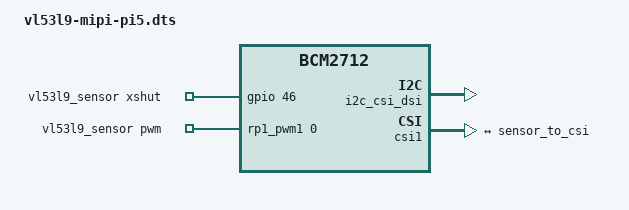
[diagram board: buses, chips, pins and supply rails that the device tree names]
// SPDX-License-Identifier: GPL-2.0-only
/*
 * VL53L9CX time-of-flight lidar (STEVAL-VL53L9) on Raspberry Pi 5 (BCM2712 + RP1).
 *
 * The VL53L9CX streams a RAW8 (datatype 0x2A, single data lane) MIPI CSI-2 image of
 * the ranging results and is configured over the camera connector I2C bus by
 * userspace (app/vl53l9_bringup). The kernel side only needs:
 *   - the RP1 CSI receiver (CFE) enabled with a 1-lane endpoint,
 *   - the connector I2C bus enabled so userspace can talk to the sensor,
 *   - a dummy CSI-2 sensor subdevice node matched by driver/dummy_cam.ko.
 *
 * XSHUT: on the 22-pin camera FFC, pin 17 (CAM_IO0) -- which the Pi 5 baseboard
 * normally uses as the camera-rail enable (cam0_reg / cam1_reg) -- reaches the
 * VL53L9's XSHUT pin. The STEVAL module has no separate power-enable net, so the
 * sensor node claims that line as xshut-gpios and the matching camN_reg is
 * disabled so it stops claiming/driving it. dummy_cam.ko then owns the line and
 * exposes /sys/devices/platform/vl53l9/xshut_{cycle,state}.
 * XSHUT HIGH = run, LOW = shutdown.
 *
 *   connector       CSI    I2C bus                  XSHUT (RP1 GPIO)  regulator
 *   MIPI1 (default) csi1   i2c_csi_dsi  -> i2c-4    46 (CD1_IO0)      cam1_reg
 *   MIPI0 (,cam0)   csi0   i2c_csi_dsi0 -> i2c-6    34 (CD0_IO0)      cam0_reg
 *
 * AP_CLK: the STEVAL ships strapped for a host-supplied reference clock on FFC
 * pin 18 (CAM_IO1 / "XCLK"). On the Pi 5 that pin is RP1 GPIO 35 (MIPI0) / 48
 * (MIPI1), which has no GPCLK function, only PWM1_CHAN0 (the fan uses
 * PWM1_CHAN3). The sensor node muxes that pin to pwm1 and dummy_cam runs channel
 * 0 at 8.33 MHz = 6 ticks of RP1's 50 MHz PWM clock, 50% duty (VL53L9 accepts
 * 6-27 MHz). Not 12 MHz: RP1 can't make it without a fractional divider, and the
 * STEVAL routes AP_CLK through a PI4ULS3V204 auto-direction level shifter rated
 * for 24 Mb/s push-pull (= a 12 MHz clock); 8.33 MHz (16.7 Mb/s) keeps margin. Boards modified to use the
 * onboard 12 MHz oscillator: load dummy_cam with ap_clk=0.
 *
 *   connector       AP_CLK pin (FFC 18)
 *   MIPI1 (default) RP1 GPIO 48 (CD1_IO1)
 *   MIPI0 (,cam0)   RP1 GPIO 35 (CD0_IO1; the kernel labels it CD0_IO0_MICDAT0)
 *
 * Every connector-specific setting (I2C bus, CSI port, XSHUT line, regulator,
 * AP_CLK pin) is switched together by the cam0 parameter, so the two variants can't disagree.
 *
 *     dtoverlay=vl53l9-mipi-pi5           # MIPI1 (main port)
 *     dtoverlay=vl53l9-mipi-pi5,cam0      # MIPI0 (second port)
 *
 * Optional: xshut_gpio=<n> overrides the XSHUT line number (applied after cam0);
 *           ap_clk_hz=<hz> changes the AP_CLK frequency (6-27 MHz; RP1 can only
 *           make 50 MHz / N, e.g. 8333333 (default), 10000000; 12500000 exceeds the
 *           board level shifter's 24 Mb/s rating).
 *
 * Build (needs the C preprocessor for the #include):
 *     make overlay      # or see README
 */
#include <dt-bindings/gpio/gpio.h>

/dts-v1/;
/plugin/;

/ {
	compatible = "brcm,bcm2712";

	i2c_frag: fragment@0 {
		target = <&i2c_csi_dsi>;
		__overlay__ {
			status = "okay";
		};
	};

	csi_frag: fragment@1 {
		target = <&csi1>;
		__overlay__ {
			status = "okay";

			port {
				csi_to_sensor: endpoint {
					remote-endpoint = <&sensor_to_csi>;
					clock-lanes = <0>;
					data-lanes = <1>;  /* VL53L9CX: single data lane */
				};
			};
		};
	};

	sensor_frag: fragment@2 {
		target-path = "/";
		__overlay__ {
			vl53l9_sensor: vl53l9 {
				compatible = "raspberrypi,dummy-csi2-sensor";
				status = "okay";

				/* Cell 1 (byte offset 4) is the GPIO number; patched by
				 * the cam0 / xshut_gpio parameters below. */
				xshut-gpios = <&gpio 46 GPIO_ACTIVE_HIGH>;

				/* AP_CLK: PWM1 channel 0 on FFC pin 18. The period
				 * cell is informational; dummy_cam programs the
				 * frequency from vl53l9,ap-clk-hz. */
				pinctrl-names = "default";
				pinctrl-0 = <&vl53l9_apclk_pins>;
				pwms = <&rp1_pwm1 0 80 0>;
				vl53l9,ap-clk-hz = <8333333>;

				port {
					sensor_to_csi: endpoint {
						remote-endpoint = <&csi_to_sensor>;
					};
				};
			};
		};
	};

	reg_frag: fragment@3 {
		target = <&cam1_reg>;
		__overlay__ {
			/* The baseboard treats this line as a camera-rail enable; on
			 * the STEVAL it is XSHUT. Left active, the fixed regulator
			 * would claim the GPIO (so dummy_cam could not) and, having no
			 * consumer, hold it LOW = sensor in shutdown. */
			status = "disabled";
		};
	};

	fragment@4 {
		target = <&rp1_gpio>;
		__overlay__ {
			vl53l9_apclk_pins: vl53l9_apclk_pins {
				function = "pwm1";
				pins = "gpio48";
				bias-disable;
			};
		};
	};

	__overrides__ {
		cam0 = <&i2c_frag>, "target:0=", <&i2c_csi_dsi0>,
		       <&csi_frag>, "target:0=", <&csi0>,
		       <&reg_frag>, "target:0=", <&cam0_reg>,
		       <&vl53l9_sensor>, "xshut-gpios:4=34",
		       <&vl53l9_apclk_pins>, "pins=gpio35";
		xshut_gpio = <&vl53l9_sensor>, "xshut-gpios:4";
		ap_clk_hz = <&vl53l9_sensor>, "vl53l9,ap-clk-hz:0";
	};
};
